# VPAC0_PAR_VPAC_MSC_CFG_VP_LSE_CFG_VP register map
Vendor: Texas Instruments
Peripheral module from a debugger description file (folder J7ES).
Registers are 32-bit, read-only, reset 0x0 unless marked. A register's access mark holds for its fields unless they carry their own. Offsets are as the file gives them; lines under a group give offsets from that group; [hi:lo] are bit positions; {n}, {i} and the like mark numbered series; 'fields as' and 'values as' point back to an identical list; <NAME> marks a mode.

## VPAC0_PAR_VPAC_MSC_CFG_VP_LSE_CFG_VP
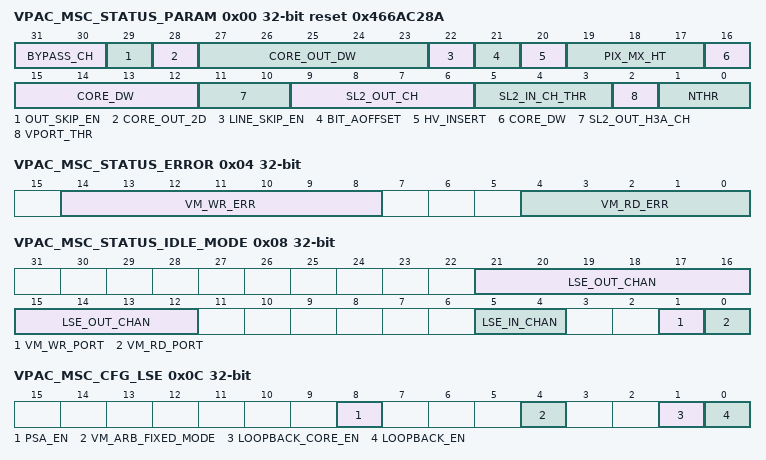
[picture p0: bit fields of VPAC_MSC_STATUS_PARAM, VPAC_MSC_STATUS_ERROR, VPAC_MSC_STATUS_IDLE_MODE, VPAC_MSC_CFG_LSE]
0x00 VPAC_MSC_STATUS_PARAM reset 0x466AC28A — The register returns the LSE compile configuration parameters.
  [31:30] BYPASS_CH — Number of available input channel selection for loopback mode
  [29] OUT_SKIP_EN — Output Auto-Skip Enable
  [28] CORE_OUT_2D — 1D or 2D output addressing mode(2D if 1)
  [27:23] CORE_OUT_DW — Core Output Channel Data Width
  [22] LINE_SKIP_EN — Source Line Inc by 2 Supported (if 1)
  [21] BIT_AOFFSET — Source nibble offset address Supported (if 1)
  [20] HV_INSERT — H/VBLANK Insertion Supported (if 1)
  [19:17] PIX_MX_HT — Core_Input Pixel Matrix Height
  [16:12] CORE_DW — Core Input Data Bus Width
  [11:10] SL2_OUT_H3A_CH — Number of SL2 H3A Output Channels
  [9:6] SL2_OUT_CH — Number of SL2 Output Channels
  [5:3] SL2_IN_CH_THR — Number of Input Channels per thread
  [2] VPORT_THR — Number of VPORT input enabled
  [1:0] NTHR — Number of threads supported
0x04 VPAC_MSC_STATUS_ERROR access not given — The register returns the LSE error status.
  [14:8] VM_WR_ERR — VBUSM I/F Last Write Error Status (access RW1C)
  [4:0] VM_RD_ERR — VBUSM I/F Last Read Error Status (access RW1C)
0x08 VPAC_MSC_STATUS_IDLE_MODE — The register returns IDLE status of LSE VBUSM port and in/output channels - 0: IDLE 1: ACTIVE
  [21:12] LSE_OUT_CHAN — Output Channel
  [5:4] LSE_IN_CHAN — Input Channel
  [1] VM_WR_PORT — SL2 vbusm I/F Write Port Status
  [0] VM_RD_PORT — SL2 vbusm I/F Read Port Status
0x0C VPAC_MSC_CFG_LSE rw — The register configures the LSE general hardware modes.
  [8] PSA_EN — Test mode Output Channel Signature Generation Enable
  [4] VM_ARB_FIXED_MODE — VBUSM Arbitration Fixed Mode select
  [1] LOOPBACK_CORE_EN — Functional path (data to HWA core) enable during loopback mode
  [0] LOOPBACK_EN — LSE loopback mode enable
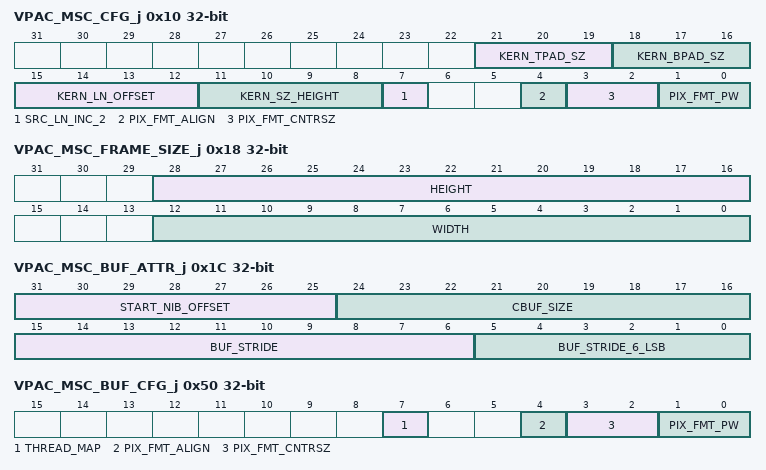
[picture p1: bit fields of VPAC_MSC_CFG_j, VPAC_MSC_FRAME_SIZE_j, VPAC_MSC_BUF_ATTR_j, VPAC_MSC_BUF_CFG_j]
0x10 VPAC_MSC_CFG_j rw — The SRC[a]_CFG register configures the input channels for the processing thread [a] Offset = 001C0810h + (j * 20h); where j = 0h to 1h
  [21:19] KERN_TPAD_SZ — Input kernel top padding lines valid=0..2 for msc
  [18:16] KERN_BPAD_SZ — Input kernel bottom padding lines valid=0..2 for msc
  [15:12] KERN_LN_OFFSET — Input kernel starting line position valid=0..4 for msc
  [11:8] KERN_SZ_HEIGHT — Actual number of input kernel lines (height) valid=1..5 for msc
  [7] SRC_LN_INC_2 — Source Line address Increment by 2 enable
  [4] PIX_FMT_ALIGN — Input Pixel Container Alignment
  [3:2] PIX_FMT_CNTRSZ — Input Pixel Container Size Sel
  [1:0] PIX_FMT_PW — Input Pixel Width Sel
0x18 VPAC_MSC_FRAME_SIZE_j rw — The SRC[a]_FRAME_SIZE register configures the frame size of all input buffers for the processing thread [a]. Offset = 001C0818h + (j * 20h); where j = 0h to 1h
  [28:16] HEIGHT — SL
  [12:0] WIDTH — SL
0x1C VPAC_MSC_BUF_ATTR_j access per field — The SRC[a]_BUF_ATTR register configures the common attributes of all SL2 source buffers for the processing thread [a]. Offset = 001C081Ch + (j * 20h); where j = 0h to 1h
  [31:25] START_NIB_OFFSET rw — Buffer Line start offset within the first SL2 data word - in half-byte (nibble) resolution
  [24:16] CBUF_SIZE rw — SL2 Circular Buffer Size (number of line buffers)
  [15:6] BUF_STRIDE rw — Buffer Stride Size
  [5:0] BUF_STRIDE_6_LSB ro — Buffer Stride Size
0x50 VPAC_MSC_BUF_CFG_j rw — The DST[a]_BUF_CFG register configures the output buffer channel [a]. Offset = 001C0850h + (j * 10h); where j = 0h to 9h
  [7] THREAD_MAP — Output Channel - thread mapping
  [4] PIX_FMT_ALIGN — Output Pixel Container Alignment
  [3:2] PIX_FMT_CNTRSZ — Output Pixel Container Size Sel
  [1:0] PIX_FMT_PW — Output Pixel Width Sel
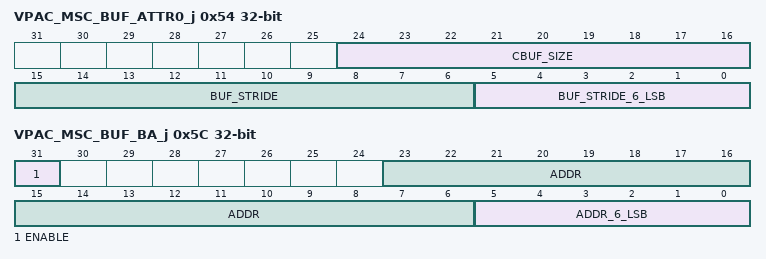
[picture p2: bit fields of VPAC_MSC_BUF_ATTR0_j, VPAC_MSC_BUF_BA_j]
0x54 VPAC_MSC_BUF_ATTR0_j access per field — The DST[a]_BUF_ATTR0 register configures the attributes of the output SL2 buffer [a]. Offset = 001C0854h + (j * 10h); where j = 0h to 9h
  [24:16] CBUF_SIZE rw — SL2 Circular Buffer Size (number of line buffers)
  [15:6] BUF_STRIDE rw — Buffer Stride Size
  [5:0] BUF_STRIDE_6_LSB ro — Buffer Stride Size
0x5C VPAC_MSC_BUF_BA_j access per field — The SRC[a]_BUF_BA register configures the base address of the SL2 source buffer for the processing thread [a]. Offset = 001C0820h + (j * 20h); where j = 0h to 1h
  [31] ENABLE rw — Input Buffer Enable
  [23:6] ADDR rw — Base Address
  [5:0] ADDR_6_LSB ro — Base Address
0x140 VPAC_MSC_PSA_SIGNATURE_y — The PSA_SIGNATURE register returns the captured PSA signature value of the last frame data of output channel [a]. Offset = 001C0940h + (y * 4h); where y = 0h to 9h
  [31:0] VALUE — 32-bit CRC signature value
0x1E0 VPAC_MSC_DBG_y — The DBG register returns the current status of internal FSM - TI internal use only. Offset = 001C09E0h + (y * 4h); where y = 0h to 4h
  [31:0] STATUS — Debug status
